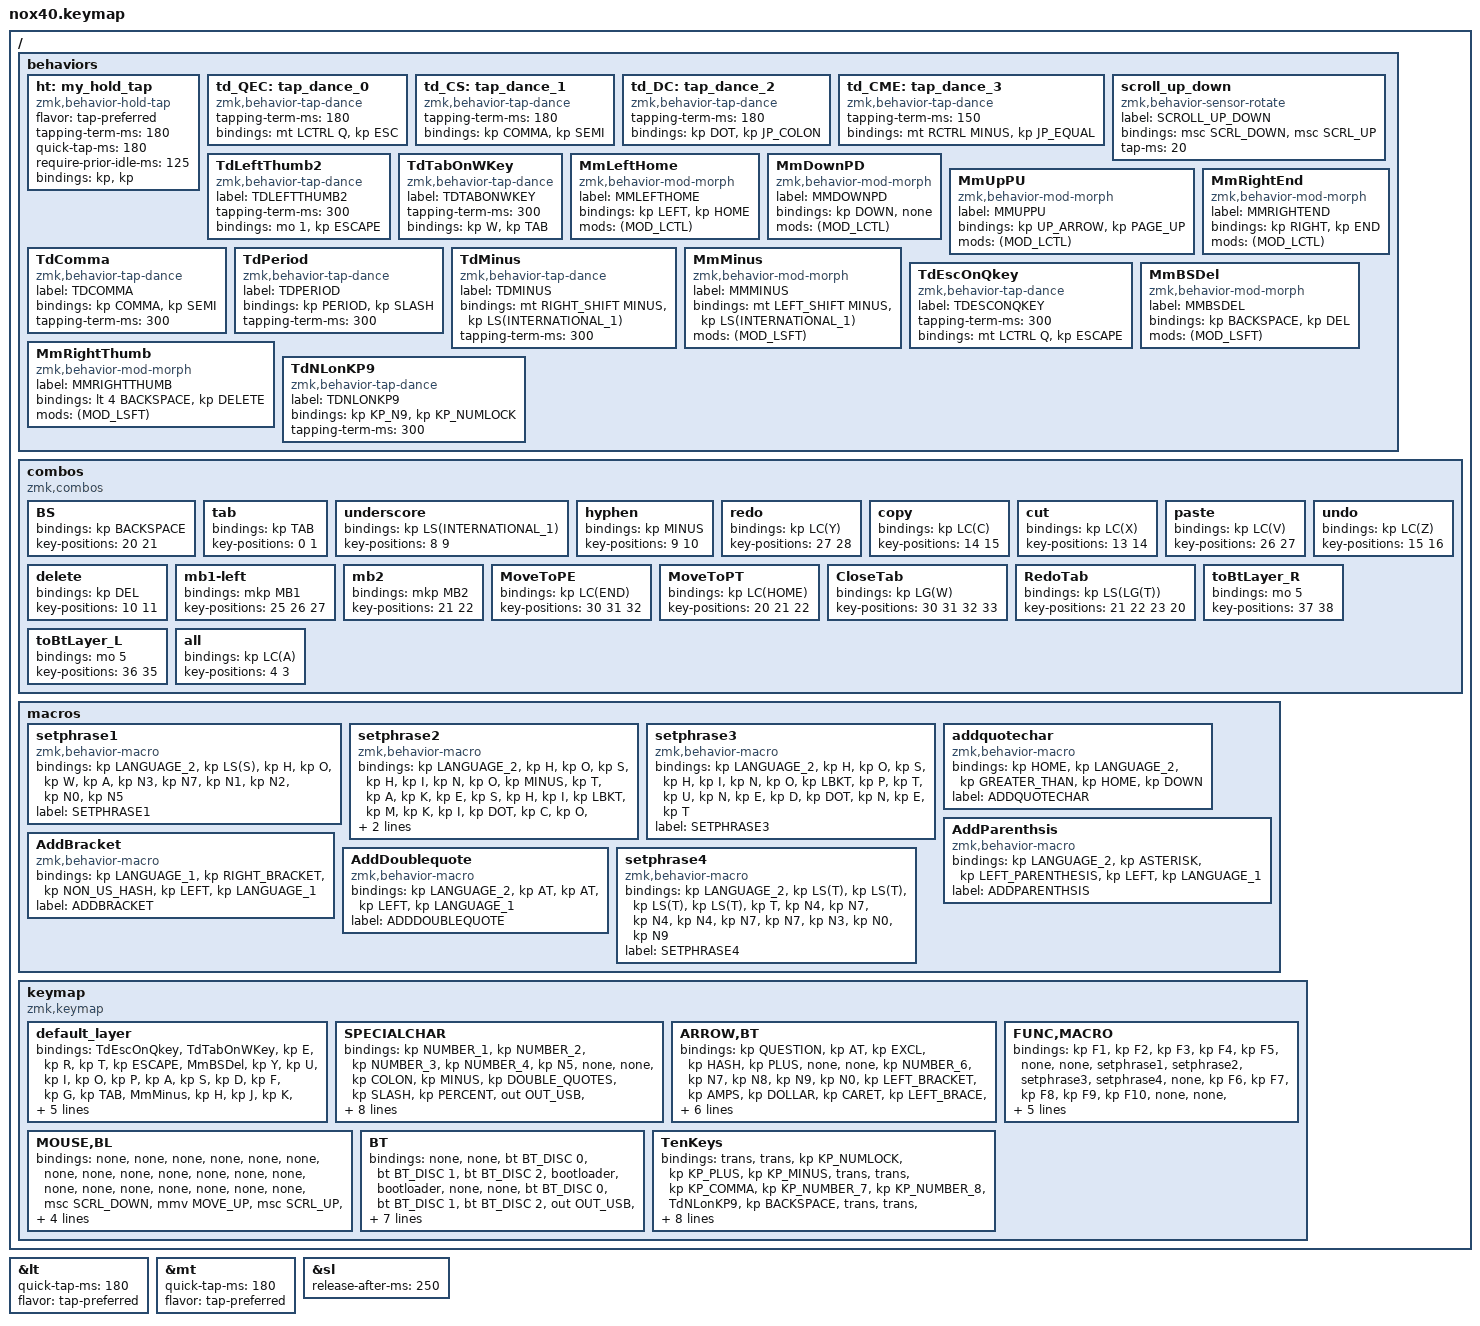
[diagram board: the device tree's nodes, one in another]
#include <behaviors.dtsi>
#include <dt-bindings/zmk/bt.h>
#include <dt-bindings/zmk/keys.h>
#include <dt-bindings/zmk/outputs.h>
#include <dt-bindings/zmk/pointing.h>

// OS設定を日本語キーボードのまま使用するための変換定義

#define JP_DQUOTE       AT                // "
#define JP_AMPERSAND    CARET             // &
#define JP_QUOTE        AMPERSAND         // '
#define JP_EQUAL        UNDER             // =
#define JP_CARET        EQUAL             // ^
#define JP_YEN          0x89              // ¥
#define JP_PLUS         COLON             // +
#define JP_TILDE        PLUS              // ~
#define JP_PIPE         LS(0x89)          // |
#define JP_AT           LEFT_BRACKET      // @
#define JP_COLON        SINGLE_QUOTE      // :
#define JP_ASTERISK     DOUBLE_QUOTES     // *
#define JP_BACKQUOTE    LEFT_BRACE        // `
#define JP_UNDERSCORE   LS(0x87)          // _
#define JP_LBRACKET     RIGHT_BRACKET     // [
#define JP_RBRACKET     BACKSLASH         // ]
#define JP_LPAREN       ASTERISK          // (
#define JP_RPAREN       LEFT_PARENTHESIS  // )
#define JP_LBRACE       RIGHT_BRACE       // {
#define JP_RBRACE       PIPE              // }
#define JP_KANA         LANGUAGE_1        // かな
#define JP_EISU         LANGUAGE_2        // 英数
#define JP_HANZEN       GRAVE             // 半角/全角

&lt {
    quick-tap-ms = <180>;
    flavor = "tap-preferred";
};

&mt {
    quick-tap-ms = <180>;
    flavor = "tap-preferred";
};

&sl { release-after-ms = <250>; };

/ {
    behaviors {
        ht: my_hold_tap {
            compatible = "zmk,behavior-hold-tap";
            #binding-cells = <2>;
            flavor = "tap-preferred";
            tapping-term-ms = <180>;
            quick-tap-ms = <180>;
            require-prior-idle-ms = <125>;
            bindings = <&kp>, <&kp>;
        };

        td_QEC: tap_dance_0 {
            compatible = "zmk,behavior-tap-dance";
            #binding-cells = <0>;
            tapping-term-ms = <180>;
            bindings = <&mt LCTRL Q>, <&kp ESC>;
        };

        td_CS: tap_dance_1 {
            compatible = "zmk,behavior-tap-dance";
            #binding-cells = <0>;
            tapping-term-ms = <180>;
            bindings = <&kp COMMA>, <&kp SEMI>;
        };

        td_DC: tap_dance_2 {
            compatible = "zmk,behavior-tap-dance";
            #binding-cells = <0>;
            tapping-term-ms = <180>;
            bindings = <&kp DOT>, <&kp JP_COLON>;
        };

        td_CME: tap_dance_3 {
            compatible = "zmk,behavior-tap-dance";
            #binding-cells = <0>;
            tapping-term-ms = <150>;
            bindings = <&mt RCTRL MINUS>, <&kp JP_EQUAL>;
        };

        scroll_up_down: scroll_up_down {
            compatible = "zmk,behavior-sensor-rotate";
            label = "SCROLL_UP_DOWN";
            #sensor-binding-cells = <0>;
            bindings = <&msc SCRL_DOWN>, <&msc SCRL_UP>;

            tap-ms = <20>;
        };

        TdLeftThumb2: TdLeftThumb2 {
            compatible = "zmk,behavior-tap-dance";
            label = "TDLEFTTHUMB2";
            #binding-cells = <0>;
            tapping-term-ms = <300>;
            bindings = <&mo 1>, <&kp ESCAPE>;
        };

        TdTabOnWKey: TdTabOnWKey {
            compatible = "zmk,behavior-tap-dance";
            label = "TDTABONWKEY";
            #binding-cells = <0>;
            tapping-term-ms = <300>;
            bindings = <&kp W>, <&kp TAB>;
        };

        MmLeftHome: MmLeftHome {
            compatible = "zmk,behavior-mod-morph";
            label = "MMLEFTHOME";
            bindings = <&kp LEFT>, <&kp HOME>;

            #binding-cells = <0>;
            mods = <(MOD_LCTL)>;
        };

        MmDownPD: MmDownPD {
            compatible = "zmk,behavior-mod-morph";
            label = "MMDOWNPD";
            bindings = <&kp DOWN>, <&none>;

            #binding-cells = <0>;
            mods = <(MOD_LCTL)>;
        };

        MmUpPU: MmUpPU {
            compatible = "zmk,behavior-mod-morph";
            label = "MMUPPU";
            bindings = <&kp UP_ARROW>, <&kp PAGE_UP>;

            #binding-cells = <0>;
            mods = <(MOD_LCTL)>;
        };

        MmRightEnd: MmRightEnd {
            compatible = "zmk,behavior-mod-morph";
            label = "MMRIGHTEND";
            bindings = <&kp RIGHT>, <&kp END>;

            #binding-cells = <0>;
            mods = <(MOD_LCTL)>;
        };

        TdComma: TdComma {
            compatible = "zmk,behavior-tap-dance";
            label = "TDCOMMA";
            #binding-cells = <0>;
            bindings = <&kp COMMA>, <&kp SEMI>;

            tapping-term-ms = <300>;
        };

        TdPeriod: TdPeriod {
            compatible = "zmk,behavior-tap-dance";
            label = "TDPERIOD";
            #binding-cells = <0>;
            bindings = <&kp PERIOD>, <&kp SLASH>;

            tapping-term-ms = <300>;
        };

        TdMinus: TdMinus {
            compatible = "zmk,behavior-tap-dance";
            label = "TDMINUS";
            #binding-cells = <0>;
            bindings = <&mt RIGHT_SHIFT MINUS>, <&kp LS(INTERNATIONAL_1)>;

            tapping-term-ms = <300>;
        };

        MmMinus: MmMinus {
            compatible = "zmk,behavior-mod-morph";
            label = "MMMINUS";
            bindings = <&mt LEFT_SHIFT MINUS>, <&kp LS(INTERNATIONAL_1)>;

            #binding-cells = <0>;
            mods = <(MOD_LSFT)>;
        };

        TdEscOnQkey: TdEscOnQkey {
            compatible = "zmk,behavior-tap-dance";
            label = "TDESCONQKEY";
            #binding-cells = <0>;
            tapping-term-ms = <300>;
            bindings = <&mt LCTRL Q>, <&kp ESCAPE>;
        };

        MmBSDel: MmBSDel {
            compatible = "zmk,behavior-mod-morph";
            label = "MMBSDEL";
            bindings = <&kp BACKSPACE>, <&kp DEL>;

            #binding-cells = <0>;
            mods = <(MOD_LSFT)>;
        };

        MmRightThumb: MmRightThumb {
            compatible = "zmk,behavior-mod-morph";
            label = "MMRIGHTTHUMB";
            bindings = <&lt 4 BACKSPACE>, <&kp DELETE>;

            #binding-cells = <0>;
            mods = <(MOD_LSFT)>;
        };

        TdNLonKP9: TdNLonKP9 {
            compatible = "zmk,behavior-tap-dance";
            label = "TDNLONKP9";
            #binding-cells = <0>;
            bindings = <&kp KP_N9>, <&kp KP_NUMLOCK>;

            tapping-term-ms = <300>;
        };
    };

    combos {
        compatible = "zmk,combos";

        BS {
            bindings = <&kp BACKSPACE>;
            key-positions = <20 21>;
        };

        tab {
            bindings = <&kp TAB>;
            key-positions = <0 1>;
        };

        underscore {
            bindings = <&kp LS(INTERNATIONAL_1)>;
            key-positions = <8 9>;
        };

        hyphen {
            bindings = <&kp MINUS>;
            key-positions = <9 10>;
        };

        redo {
            bindings = <&kp LC(Y)>;
            key-positions = <27 28>;
        };

        copy {
            bindings = <&kp LC(C)>;
            key-positions = <14 15>;
        };

        cut {
            bindings = <&kp LC(X)>;
            key-positions = <13 14>;
        };

        paste {
            bindings = <&kp LC(V)>;
            key-positions = <26 27>;
        };

        undo {
            bindings = <&kp LC(Z)>;
            key-positions = <15 16>;
        };

        delete {
            bindings = <&kp DEL>;
            key-positions = <10 11>;
        };

        mb1-left {
            bindings = <&mkp MB1>;
            key-positions = <25 26 27>;
        };

        mb2 {
            bindings = <&mkp MB2>;
            key-positions = <21 22>;
        };

        MoveToPE {
            bindings = <&kp LC(END)>;
            key-positions = <30 31 32>;
        };

        MoveToPT {
            bindings = <&kp LC(HOME)>;
            key-positions = <20 21 22>;
        };

        CloseTab {
            bindings = <&kp LG(W)>;
            key-positions = <30 31 32 33>;
        };

        RedoTab {
            bindings = <&kp LS(LG(T))>;
            key-positions = <21 22 23 20>;
        };

        toBtLayer_R {
            bindings = <&mo 5>;
            key-positions = <37 38>;
        };

        toBtLayer_L {
            bindings = <&mo 5>;
            key-positions = <36 35>;
        };

        all {
            bindings = <&kp LC(A)>;
            key-positions = <4 3>;
        };
    };

    macros {
        setphrase1: setphrase1 {
            compatible = "zmk,behavior-macro";
            #binding-cells = <0>;
            bindings = <&kp LANGUAGE_2 &kp LS(S) &kp H &kp O &kp W &kp A &kp N3 &kp N7 &kp N1 &kp N2 &kp N0 &kp N5>;
            label = "SETPHRASE1";
        };

        setphrase2: setphrase2 {
            compatible = "zmk,behavior-macro";
            #binding-cells = <0>;
            bindings = <&kp LANGUAGE_2 &kp H &kp O &kp S &kp H &kp I &kp N &kp O &kp MINUS &kp T &kp A &kp K &kp E &kp S &kp H &kp I &kp LBKT &kp M &kp K &kp I &kp DOT &kp C &kp O &kp DOT &kp J &kp P>;
            label = "SETPHRASE2";
        };

        setphrase3: setphrase3 {
            compatible = "zmk,behavior-macro";
            #binding-cells = <0>;
            bindings = <&kp LANGUAGE_2 &kp H &kp O &kp S &kp H &kp I &kp N &kp O &kp LBKT &kp P &kp T &kp U &kp N &kp E &kp D &kp DOT &kp N &kp E &kp T>;
            label = "SETPHRASE3";
        };

        addquotechar: addquotechar {
            compatible = "zmk,behavior-macro";
            #binding-cells = <0>;
            bindings = <&kp HOME &kp LANGUAGE_2 &kp GREATER_THAN &kp HOME &kp DOWN>;
            label = "ADDQUOTECHAR";
        };

        AddParenthsis: AddParenthsis {
            compatible = "zmk,behavior-macro";
            #binding-cells = <0>;
            bindings = <&kp LANGUAGE_2 &kp ASTERISK &kp LEFT_PARENTHESIS &kp LEFT &kp LANGUAGE_1>;
            label = "ADDPARENTHSIS";
        };

        AddBracket: AddBracket {
            compatible = "zmk,behavior-macro";
            #binding-cells = <0>;
            bindings = <&kp LANGUAGE_1 &kp RIGHT_BRACKET &kp NON_US_HASH &kp LEFT &kp LANGUAGE_1>;
            label = "ADDBRACKET";
        };

        AddDoublequote: AddDoublequote {
            compatible = "zmk,behavior-macro";
            #binding-cells = <0>;
            bindings = <&kp LANGUAGE_2 &kp AT &kp AT &kp LEFT &kp LANGUAGE_1>;
            label = "ADDDOUBLEQUOTE";
        };

        setphrase4: setphrase4 {
            compatible = "zmk,behavior-macro";
            #binding-cells = <0>;
            bindings = <&kp LANGUAGE_2 &kp LS(T) &kp LS(T) &kp LS(T) &kp LS(T) &kp T &kp N4 &kp N7 &kp N4 &kp N4 &kp N7 &kp N7 &kp N3 &kp N0 &kp N9>;
            label = "SETPHRASE4";
        };
    };

    keymap {
        compatible = "zmk,keymap";

        default_layer {
            bindings = <
&TdEscOnQkey  &TdTabOnWKey  &kp E  &kp R  &kp T  &kp ESCAPE  &MmBSDel  &kp Y  &kp U  &kp I  &kp O  &kp P  &kp A  &kp S  &kp D  &kp F  &kp G  &kp TAB  &MmMinus  &kp H  &kp J  &kp K  &lt 3 L  &kp RET  &mt LSHFT Z  &mt LEFT_WIN X  &kp C  &kp V  &kp B  &kp N  &kp M  &TdComma  &TdPeriod  &mt RIGHT_SHIFT SLASH  &kp LALT  &lt 6 DELETE  &lt 1 MINUS  &lt 2 SPACE  &MmRightThumb  &kp LS(LG(NUMBER_4))
            >;
        };

        SPECIALCHAR {
            bindings = <
&kp NUMBER_1  &kp NUMBER_2  &kp NUMBER_3  &kp NUMBER_4  &kp N5  &none  &none  &kp COLON  &kp MINUS  &kp DOUBLE_QUOTES  &kp SLASH  &kp PERCENT  &out OUT_USB  &out OUT_BLE  &bt BT_SEL 0  &bt BT_SEL 1  &bt BT_SEL 2  &none  &none  &kp RIGHT_BRACKET  &kp ASTERISK  &kp LEFT_PARENTHESIS  &kp NON_US_HASH  &none  &none  &none  &bt BT_CLR_ALL  &bt BT_CLR  &none  &kp UNDER  &kp SINGLE_QUOTE  &kp SEMICOLON  &kp LS(INTERNATIONAL_1)  &kp RIGHT_SHIFT  &trans  &trans  &trans  &trans  &trans  &trans
            >;
        };

        ARROW,BT {
            bindings = <
&kp QUESTION  &kp AT  &kp EXCL  &kp HASH  &kp PLUS  &none  &none  &kp NUMBER_6  &kp N7  &kp N8  &kp N9  &kp N0  &kp LEFT_BRACKET  &kp AMPS  &kp DOLLAR  &kp CARET  &kp LEFT_BRACE  &none  &none  &kp LEFT  &kp DOWN  &kp UP_ARROW  &kp RIGHT  &none  &trans  &kp DOUBLE_QUOTES  &kp EQUAL  &kp LS(INTERNATIONAL_3)  &kp INTERNATIONAL_3  &kp HOME  &kp PAGE_DOWN  &kp PAGE_UP  &kp END  &none  &trans  &trans  &trans  &trans  &trans  &trans
            >;
        };

        FUNC,MACRO {
            bindings = <
&kp F1  &kp F2  &kp F3  &kp F4  &kp F5  &none  &none  &setphrase1  &setphrase2  &setphrase3  &setphrase4  &none  &kp F6  &kp F7  &kp F8  &kp F9  &kp F10  &none  &none  &kp LANGUAGE_2  &kp LANGUAGE_1  &addquotechar  &none  &none  &kp F11  &kp F12  &none  &none  &none  &AddParenthsis  &AddBracket  &AddDoublequote  &none  &none  &trans  &trans  &trans  &trans  &trans  &trans
            >;
        };

        MOUSE,BL {
            bindings = <
&none  &none  &none  &none  &none  &none  &none  &none  &none  &none  &none  &none  &none  &none  &none  &none  &none  &none  &none  &none  &msc SCRL_DOWN  &mmv MOVE_UP  &msc SCRL_UP  &none  &none  &none  &none  &none  &none  &mkp LCLK  &mmv MOVE_LEFT  &mmv MOVE_DOWN  &mmv MOVE_RIGHT  &mkp RCLK  &trans  &trans  &trans  &trans  &trans  &trans
            >;
        };

        BT {
            bindings = <
&none  &none  &bt BT_DISC 0  &bt BT_DISC 1  &bt BT_DISC 2  &bootloader  &bootloader  &none  &none  &bt BT_DISC 0  &bt BT_DISC 1  &bt BT_DISC 2  &out OUT_USB  &out OUT_BLE  &bt BT_SEL 0  &bt BT_SEL 1  &bt BT_SEL 2  &none  &none  &out OUT_USB  &out OUT_BLE  &bt BT_SEL 0  &bt BT_SEL 1  &bt BT_SEL 2  &none  &none  &bt BT_CLR_ALL  &bt BT_CLR  &none  &none  &none  &bt BT_CLR_ALL  &bt BT_CLR  &none  &none  &none  &none  &none  &none  &none
            >;
        };

        TenKeys {
            bindings = <
&trans  &trans  &kp KP_NUMLOCK  &kp KP_PLUS  &kp KP_MINUS  &trans  &trans  &kp KP_COMMA  &kp KP_NUMBER_7  &kp KP_NUMBER_8  &TdNLonKP9  &kp BACKSPACE  &trans  &trans  &trans  &kp KP_SLASH  &kp KP_MULTIPLY  &trans  &trans  &kp KP_DOT  &kp KP_NUMBER_4  &kp KP_NUMBER_5  &kp KP_NUMBER_6  &kp KP_ENTER  &trans  &trans  &trans  &kp UNDER  &kp SINGLE_QUOTE  &kp KP_NUMBER_0  &kp KP_NUMBER_1  &kp KP_NUMBER_2  &kp KP_NUMBER_3  &trans  &trans  &trans  &trans  &kp KP_N0  &trans  &trans
            >;
        };
    };
};
